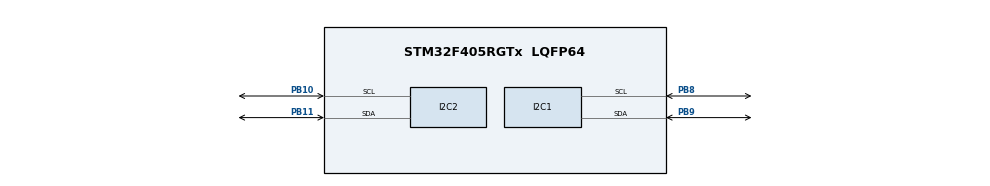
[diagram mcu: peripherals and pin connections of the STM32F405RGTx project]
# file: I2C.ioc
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I2C1.DutyCycle=I2C_DUTYCYCLE_16_9
I2C1.NoStretchMode=I2C_NOSTRETCH_ENABLED
I2C2.DutyCycle=I2C_DUTYCYCLE_16_9
I2C2.NoStretchMode=I2C_NOSTRETCH_ENABLED
I2C2.OwnAddress1=111
Mcu.Family=STM32F4
Mcu.Name=STM32F405RGTx
Mcu.Package=LQFP64
NVIC.I2C2_ER_IRQn=true\:0\:0
NVIC.I2C2_EV_IRQn=true\:0\:0
NVIC.PriorityGroup=NVIC_PRIORITYGROUP_0
PB10.GPIO_Mode=GPIO_MODE_AF_OD
PB10.GPIO_PuPd=GPIO_PULLUP
PB10.GPIO_Speed=GPIO_SPEED_HIGH
PB10.Mode=I2C
PB10.Signal=I2C2_SCL
PB11.GPIO_Mode=GPIO_MODE_AF_OD
PB11.GPIO_PuPd=GPIO_PULLUP
PB11.GPIO_Speed=GPIO_SPEED_HIGH
PB11.Mode=I2C
PB11.Signal=I2C2_SDA
PB8.GPIO_Mode=GPIO_MODE_AF_OD
PB8.GPIO_PuPd=GPIO_PULLUP
PB8.GPIO_Speed=GPIO_SPEED_HIGH
PB8.Mode=I2C
PB8.Signal=I2C1_SCL
PB9.GPIO_Mode=GPIO_MODE_AF_OD
PB9.GPIO_PuPd=GPIO_PULLUP
PB9.GPIO_Speed=GPIO_SPEED_HIGH
PB9.Mode=I2C
PB9.Signal=I2C1_SDA
PH0-OSC_IN.Mode=HSE-External-Oscillator
PH0-OSC_IN.Signal=RCC_OSC_IN
PH1-OSC_OUT.Mode=HSE-External-Oscillator
PH1-OSC_OUT.Signal=RCC_OSC_OUT
ProjectManager.TargetToolchain=EWARM 6.70
RCC.APB1CLKDivider=RCC_HCLK_DIV4
RCC.APB2CLKDivider=RCC_HCLK_DIV2
RCC.HSE_VALUE=8000000
RCC.HSI_VALUE=16000000
RCC.LSE_VALUE=32768
RCC.PLLM=8
RCC.PLLN=336
RCC.PLLSource=RCC_PLLSOURCE_HSE
RCC.SYSCLKSource=RCC_SYSCLKSOURCE_PLLCLK

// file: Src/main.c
/**
  ******************************************************************************
  * File Name          : main.c
  * Date               : 30/10/2014 10:03:28
  * Description        : Main program body
  ******************************************************************************
  *
  * COPYRIGHT(c) 2014 STMicroelectronics
  *
  * Redistribution and use in source and binary forms, with or without modification,
  * are permitted provided that the following conditions are met:
  *   1. Redistributions of source code must retain the above copyright notice,
  *      this list of conditions and the following disclaimer.
  *   2. Redistributions in binary form must reproduce the above copyright notice,
  *      this list of conditions and the following disclaimer in the documentation
  *      and/or other materials provided with the distribution.
  *   3. Neither the name of STMicroelectronics nor the names of its contributors
  *      may be used to endorse or promote products derived from this software
  *      without specific prior written permission.
  *
  * THIS SOFTWARE IS PROVIDED BY THE COPYRIGHT HOLDERS AND CONTRIBUTORS "AS IS"
  * AND ANY EXPRESS OR IMPLIED WARRANTIES, INCLUDING, BUT NOT LIMITED TO, THE
  * IMPLIED WARRANTIES OF MERCHANTABILITY AND FITNESS FOR A PARTICULAR PURPOSE ARE
  * DISCLAIMED. IN NO EVENT SHALL THE COPYRIGHT HOLDER OR CONTRIBUTORS BE LIABLE
  * FOR ANY DIRECT, INDIRECT, INCIDENTAL, SPECIAL, EXEMPLARY, OR CONSEQUENTIAL
  * DAMAGES (INCLUDING, BUT NOT LIMITED TO, PROCUREMENT OF SUBSTITUTE GOODS OR
  * SERVICES; LOSS OF USE, DATA, OR PROFITS; OR BUSINESS INTERRUPTION) HOWEVER
  * CAUSED AND ON ANY THEORY OF LIABILITY, WHETHER IN CONTRACT, STRICT LIABILITY,
  * OR TORT (INCLUDING NEGLIGENCE OR OTHERWISE) ARISING IN ANY WAY OUT OF THE USE
  * OF THIS SOFTWARE, EVEN IF ADVISED OF THE POSSIBILITY OF SUCH DAMAGE.
  *
  ******************************************************************************
  */

#include "stm32f4xx_hal.h"

I2C_HandleTypeDef hi2c1;
I2C_HandleTypeDef hi2c2;

/* USER CODE BEGIN 0 */
#define SIZE 5
__IO uint8_t MasterTX[SIZE] = {1,2,3,4,5};
__IO uint8_t SlaveRX[SIZE];
void HAL_I2C_SlaveRxCpltCallback(I2C_HandleTypeDef *hi2c);
/* USER CODE END 0 */

void SystemClock_Config(void);
static void MX_GPIO_Init(void);
static void MX_I2C1_Init(void);
static void MX_I2C2_Init(void);

int main(void)
{

  /* MCU Configuration----------------------------------------------------------*/

  /* Reset of all peripherals, Initializes the Flash interface and the Systick. */
  HAL_Init();

  /* Configure the system clock */
  SystemClock_Config();

  /* System interrupt init*/
  /* Sets the priority grouping field */
  HAL_NVIC_SetPriorityGrouping(NVIC_PRIORITYGROUP_0);
  HAL_NVIC_SetPriority(SysTick_IRQn, 0, 0);

  /* Initialize all configured peripherals */
  MX_GPIO_Init();
  MX_I2C1_Init();
  MX_I2C2_Init();

  /* USER CODE BEGIN 2 */
  HAL_I2C_Slave_Receive_IT(&hi2c2, (uint8_t*)SlaveRX, SIZE);
  /* USER CODE END 2 */

  /* USER CODE BEGIN 3 */
  /* Infinite loop */
  while (1)
  {
    HAL_I2C_Master_Transmit(&hi2c1, 111, (uint8_t*)MasterTX, SIZE, 10000);
  }
  /* USER CODE END 3 */

}

/** System Clock Configuration
*/
void SystemClock_Config(void)
{

  RCC_ClkInitTypeDef RCC_ClkInitStruct;
  RCC_OscInitTypeDef RCC_OscInitStruct;

  __PWR_CLK_ENABLE();

  __HAL_PWR_VOLTAGESCALING_CONFIG(PWR_REGULATOR_VOLTAGE_SCALE1);

  RCC_OscInitStruct.OscillatorType = RCC_OSCILLATORTYPE_HSE;
  RCC_OscInitStruct.HSEState = RCC_HSE_ON;
  RCC_OscInitStruct.PLL.PLLState = RCC_PLL_ON;
  RCC_OscInitStruct.PLL.PLLSource = RCC_PLLSOURCE_HSE;
  RCC_OscInitStruct.PLL.PLLM = 8;
  RCC_OscInitStruct.PLL.PLLN = 336;
  RCC_OscInitStruct.PLL.PLLP = RCC_PLLP_DIV2;
  RCC_OscInitStruct.PLL.PLLQ = 4;
  HAL_RCC_OscConfig(&RCC_OscInitStruct);

  RCC_ClkInitStruct.ClockType = RCC_CLOCKTYPE_SYSCLK|RCC_CLOCKTYPE_PCLK1
                              |RCC_CLOCKTYPE_PCLK2;
  RCC_ClkInitStruct.SYSCLKSource = RCC_SYSCLKSOURCE_PLLCLK;
  RCC_ClkInitStruct.AHBCLKDivider = RCC_SYSCLK_DIV1;
  RCC_ClkInitStruct.APB1CLKDivider = RCC_HCLK_DIV4;
  RCC_ClkInitStruct.APB2CLKDivider = RCC_HCLK_DIV2;
  HAL_RCC_ClockConfig(&RCC_ClkInitStruct, FLASH_LATENCY_5);

}

/* I2C1 init function */
void MX_I2C1_Init(void)
{

  hi2c1.Instance = I2C1;
  hi2c1.Init.ClockSpeed = 100000;
  hi2c1.Init.DutyCycle = I2C_DUTYCYCLE_16_9;
  hi2c1.Init.OwnAddress1 = 0;
  hi2c1.Init.AddressingMode = I2C_ADDRESSINGMODE_7BIT;
  hi2c1.Init.DualAddressMode = I2C_DUALADDRESS_DISABLED;
  hi2c1.Init.OwnAddress2 = 0;
  hi2c1.Init.GeneralCallMode = I2C_GENERALCALL_DISABLED;
  hi2c1.Init.NoStretchMode = I2C_NOSTRETCH_ENABLED;
  HAL_I2C_Init(&hi2c1);

}

/* I2C2 init function */
void MX_I2C2_Init(void)
{

  hi2c2.Instance = I2C2;
  hi2c2.Init.ClockSpeed = 100000;
  hi2c2.Init.DutyCycle = I2C_DUTYCYCLE_16_9;
  hi2c2.Init.OwnAddress1 = 111;
  hi2c2.Init.AddressingMode = I2C_ADDRESSINGMODE_7BIT;
  hi2c2.Init.DualAddressMode = I2C_DUALADDRESS_DISABLED;
  hi2c2.Init.OwnAddress2 = 0;
  hi2c2.Init.GeneralCallMode = I2C_GENERALCALL_DISABLED;
  hi2c2.Init.NoStretchMode = I2C_NOSTRETCH_ENABLED;
  HAL_I2C_Init(&hi2c2);

}

/** Configure pins as
        * Analog
        * Input
        * Output
        * EVENT_OUT
        * EXTI
*/
void MX_GPIO_Init(void)
{

  /* GPIO Ports Clock Enable */
  __GPIOH_CLK_ENABLE();
  __GPIOB_CLK_ENABLE();

}

/* USER CODE BEGIN 4 */
void HAL_I2C_SlaveRxCpltCallback(I2C_HandleTypeDef *hi2c)
{
  if(hi2c->Instance==hi2c2.Instance)
  {
    HAL_I2C_Slave_Receive_IT(&hi2c2, (uint8_t*)SlaveRX, SIZE);
  }
}
/* USER CODE END 4 */

/************************ (C) COPYRIGHT STMicroelectronics *****END OF FILE****/
